# CY8C5868AXI_LP035 register map
File version: 0.1
Registers are 8-bit, read-write, no defined reset value unless marked. A register's access mark holds for its fields unless they carry their own. Offsets are from the block's base; [hi:lo] are bit positions; {n}, {i} and the like mark numbered series; 'fields as' and 'values as' point back to an identical list.

## Status_Reg_1
Base 0x00000000
0x40006462 Status_Reg_1_STATUS_REG
0x40006482 Status_Reg_1_MASK_REG
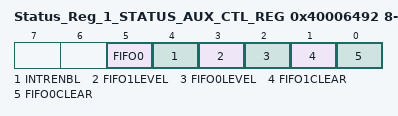
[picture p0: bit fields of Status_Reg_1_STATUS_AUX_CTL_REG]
0x40006492 Status_Reg_1_STATUS_AUX_CTL_REG
  [5] FIFO0 — FIFO0 clear
    1=ENABLED (Enable counter); 0=DISABLED (Disable counter)
  [4] INTRENBL — Enables or disables the Interrupt
    1=ENABLED (Interrupt enabled); 0=DISABLED (Interrupt disabled)
  [3] FIFO1LEVEL — FIFO level
    1=ENABLED (FIFO LVL: input mode: FIFO at least 1/2 empty; output mode: FIFO at least 1/2 full); 0=DISABLED (FIFO LVL: input mode: FIFO not full; output mode: FIFO not empty)
  [2] FIFO0LEVEL — FIFO level
    values as FIFO1LEVEL
  [1] FIFO1CLEAR — FIFO clear
    1=ENABLED (Clear FIFO state); 0=DISABLED (Normal FIFO operation)
  [0] FIFO0CLEAR — FIFO clear
    values as FIFO1CLEAR

## Control_Reg_1
Base 0x00000000
0x40006476 Control_Reg_1_CONTROL_REG

## I2C_1
Base 0x00000000
0x40006404 I2C_1_DATA — I2C Data Register
  [7:0] data — Read received data or write data to transmit.
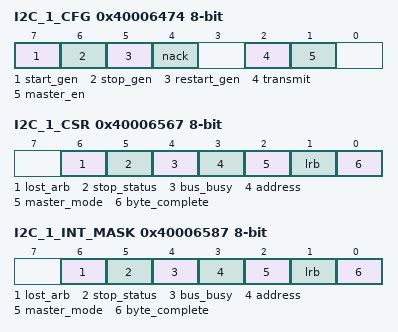
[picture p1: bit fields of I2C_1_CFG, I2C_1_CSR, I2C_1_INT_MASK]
0x40006474 I2C_1_CFG — I2C Configuration Register
  [7] start_gen — Set to 1 to generate a Start condition on the bus. This bit must be cleared by firmware before initiating the next transaction.
  [6] stop_gen — Set to 1 to generate a Stop condition on the bus. This bit must be cleared by firmware before initiating the next transaction.
  [5] restart_gen — Set to 1 to generate a Restart condition on the bus. This bit must be cleared by firmware after a Restart condition is generated.
  [4] nack — Set to 1 to NAK the next read byte. Clear to ACK next read byte. This bit must be cleared by firmware between bytes.
  [2] transmit — Set to 1 to set the current mode to transmit or clear to 0 to receive a byte of data. This bit must be cleared by firmware before starting the next transmit or receive transaction.
  [1] master_en — Set to 1 to enable the master functionality.
0x40006567 I2C_1_CSR — I2C Status Register
  [6] lost_arb ro — If set, indicates arbitration was lost (multi-master and multi-master-slave modes).
  [5] stop_status ro — If set, indicates a Stop condition was detected on the bus.
  [4] bus_busy ro — If set, indicates the bus is busy. Data is currently being transmitted or received.
  [3] address ro — Address detection. If set, indicates that an address byte was sent.
  [2] master_mode ro — Indicates that a valid Start condition was generated and a hardware device is operating as bus master.
  [1] lrb ro — Last Received Bit. Indicates the state of the last received bit, which is the ACK/NAK received for the last byte transmitted. Cleared = ACK and set = NAK.
  [0] byte_complete ro — Transmit or receive status since the last read of this register. In Transmit mode this bit indicates that eight bits of data plus ACK/NAK have been transmitted since the last read. In Receive mode this bit indicates that eight bits of data have been received since the last read of this register.
0x40006587 I2C_1_INT_MASK — I2C Interrupt Enable Mask
  [6] lost_arb — Enables interrupt from the corresponding bit in status register.
  [5] stop_status — Enables interrupt from the corresponding bit in status register.
  [4] bus_busy — Enables interrupt from the corresponding bit in status register.
  [3] address — Enables interrupt from the corresponding bit in status register.
  [2] master_mode — Enables interrupt from the corresponding bit in status register.
  [1] lrb — Enables interrupt from the corresponding bit in status register.
  [0] byte_complete — Enables interrupt from the corresponding bit in status register.

## LED3Drive
Base 0x00000000
0x40006477 LED3Drive_CONTROL_REG

## Opamp_4
Base 0x00000000
0x400043A4 PM_ACT_CFG4 — Active Power Mode Configuration Register 4
  [3:0] EN_OPAMP — Enables subsystems during active power mode
    0=Blk_0 (Enables analog linear output buffer for Opamp block 0); 2=Blk_1 (Enables analog linear output buffer for Opamp block 1); 4=Blk_2 (Enables analog linear output buffer for Opamp block 2); 8=Blk_3 (Enables analog linear output buffer for Opamp block 3)
0x400043B4 PM_STBY_CFG4 — Standby Power Mode Configuration Register 4
  [3:0] EN_OPAMP — Enables subsystems during standby power mode
    values as PM_ACT_CFG4.EN_OPAMP
0x40004624 OPAMP__TR0 — Analog Output Buffer Trim Register 0
  [4:0] offset_trim — Offset Trim: 420uV typical step size; +/- 6.8mV offset trimmable range
0x40004625 OPAMP__TR1 — Analog Output Buffer Trim Register 1
0x4000585C OPAMP__CR — Analog Output Buffer Configuration Register
  [1:0] pwr_mode — Power Mode
    0=Default_Fast (Default Power mode Fast); 1=Slow (Power Mode Slow); 2=Medium (Power Mode Medium); 3=Fast (Power Mode Fast)
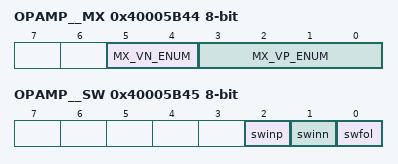
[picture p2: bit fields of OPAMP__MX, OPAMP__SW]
0x40005B44 OPAMP__MX — Analog Buffer Input Selection Register
  [5:4] MX_VN_ENUM — MUX select VN (Negative terminal input)
    0=OPAMP0_MX_VN_DEFAULT (Default - Not Connected (NC)); 1=OPAMP0_MX_VN_AG4 (MUX Selection AGL(4)); 2=OPAMP0_MX_VN_AG6 (MUX Selection AGL(6)); 3=OPAMP0_MX_VN_0x3 (Reserved (NC))
  [3:0] MX_VP_ENUM — MUX select VP (Positive terminal input)
    0=OPAMP0_MX_VP_DEFAULT (Default - Not Connected (NC)); {v}=OPAMP0_MX_VP_AG{v+3} (MUX Selection AGL({v+3})) (v=1..4); {v}=OPAMP0_MX_VP_ABUS{v-5} (MUX Selection ABUSL({v-5})) (v=5..8); 9=OPAMP0_MX_VP_VREF (MUX Selection: OPAMP Voltage Reference); {v}=OPAMP0_MX_VP_H_{0x0+v} (Reserved (NC)) (v=10..15)
0x40005B45 OPAMP__SW — Analog Buffer Routing Switch Register
  [2] swinp — Switch Enable Positive Input
  [1] swinn — Switch Enable Negative Input
  [0] swfol — Switch Enable Follow
